# JTAG register map
Vendor: litex
Registers are 32-bit, read-write, reset 0x0 unless marked. A register's access mark holds for its fields unless they carry their own. Offsets are from the block's base; [hi:lo] are bit positions; {n}, {i} and the like mark numbered series.

## BTEVENTS
Base 0xF000D000
0x00 EV_STATUS
  [1:0] status
0x04 EV_PENDING
  [1:0] pending
0x08 EV_ENABLE
  [1:0] enable

## MESSIBLE
Base 0xF000E000
0x00 IN — Write half of the FIFO to send data out the Messible. Writing to this register advances the write pointer automatically.
  [7:0] in
0x04 OUT ro — Read half of the FIFO to receive data on the Messible. Reading from this register advances the read pointer automatically.
  [7:0] out
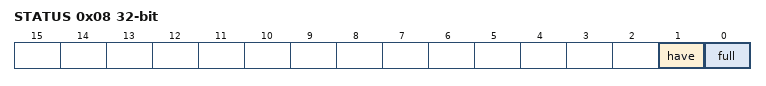
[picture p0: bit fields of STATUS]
0x08 STATUS ro
  [1] have — `1` if data can be read from the OUT FIFO.
  [0] full — `0` if more data can fit into the IN FIFO.

## TICKTIMER
Base 0xF000F000
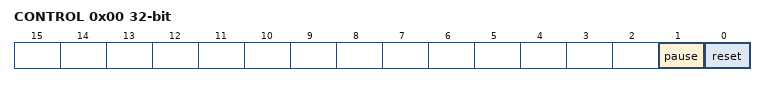
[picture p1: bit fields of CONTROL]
0x00 CONTROL
  [1] pause — Write a `1` to this field to pause counting, 0 for free-run
  [0] reset — Write a `1` to this bit to reset the count to 0
0x04 TIME1 ro — Bits 32-63 of `TICKTIMER_TIME`. Elapsed time in systicks
  [31:0] time
0x08 TIME0 ro — Bits 0-31 of `TICKTIMER_TIME`.
  [31:0] time

## POWER
Base 0xF0010000
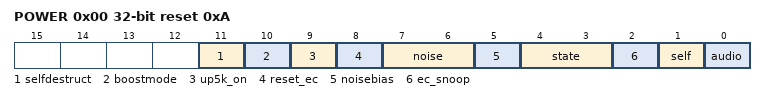
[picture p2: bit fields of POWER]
0x00 POWER reset 0xA
  [11] selfdestruct — Set this bit to clear BBRAM AES key (if used) and cut power in an annoying-to- reset fashion
  [10] boostmode — Writing a `1` causes the USB port to source 5V. To be active only when playing the host role.
  [9] up5k_on — Writing a `1` pulses the UP5K domain to turn on
  [8] reset_ec — Writing a `1` forces EC into reset. Requires write of `0` to release reset.
  [7:6] noise — Controls which of two noise channels are active; all combos valid. noisebias must be on first.
  [5] noisebias — Writing `1` enables the primary bias supply for the noise generator
  [4:3] state — Current SoC power state. 0x=off or not ready, 10=on and safe to shutdown, 11=on and not safe to shut down, resets to 01 to allow extSRAM access immediately during init
  [2] ec_snoop — Writing `1` allows the insecure EC to snoop a couple keyboard pads for wakeup key sequence recognition
  [1] self — Writing `1` forces self power-on (overrides the EC's ability to power me down)
  [0] audio — Write `1` to power on the audio subsystem
0x04 VIBE — Vibration motor configuration register
  [0] vibe — Turn on vibration motor
0x08 EV_STATUS
  [0] status
0x0C EV_PENDING
  [0] pending
0x10 EV_ENABLE
  [0] enable

## SPINOR
Base 0xF0011000
0x00 CONFIG reset 0xA
  [4:0] dummy — Number of dummy cycles
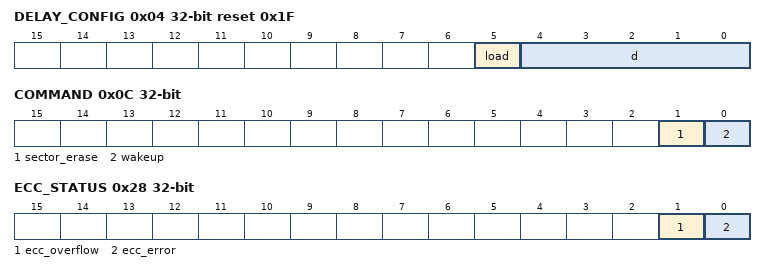
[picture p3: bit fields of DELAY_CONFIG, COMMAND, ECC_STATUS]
0x04 DELAY_CONFIG reset 0x1F
  [5] load — Force delay taps to delay_d
  [4:0] d — Delay amount; each increment is 78ps
0x08 DELAY_STATUS ro
  [4:0] q — Readback of current delay amount, useful if inc/ce is used to set
0x0C COMMAND — Write individual bits to issue special commands to SPI; setting multiple bits at once leads to undefined behavior.
  [1] sector_erase — Erase a sector
  [0] wakeup — Sequence through init & wakeup routine
0x10 SECTOR — Sector to erase
0x14 STATUS ro — Interface status
  [0] wip — Operation in progress (write or erease)
0x18 EV_STATUS
  [0] status
0x1C EV_PENDING
  [0] pending
0x20 EV_ENABLE
  [0] enable
0x24 ECC_ADDRESS ro
  [31:0] ecc_address — Address of the most recent ECC event
0x28 ECC_STATUS ro
  [1] ecc_overflow — More than one ECS_N event has happened since th last time ecc_address was checked
  [0] ecc_error — Live status of the ECS_N bit (ECC error on current packet when low)

## KEYBOARD
Base 0xF0012000
{0x0+4i} ROW{i}DAT ro (i=0..8) — Column data for the given row
  [9:0] row{i}dat
0x24 EV_STATUS
  [0] status
0x28 EV_PENDING
  [0] pending
0x2C EV_ENABLE
  [0] enable
0x30 ROWCHANGE ro — The rows that changed at the point of interrupt generation. Does not update again until the interrupt is serviced.
  [8:0] rowchange

## GPIO
Base 0xF0013000
0x00 OUTPUT — Values to appear on GPIO when respective `drive` bit is asserted
  [5:0] output
0x04 INPUT ro — Value measured on the respective GPIO pin
  [5:0] input
0x08 DRIVE — When a bit is set to `1`, the respective pad drives its value out
  [5:0] drive
0x0C INTENA ro — Enable interrupts when a respective bit is set
  [5:0] intena
0x10 INTPOL ro — When a bit is `1`, falling-edges cause interrupts. Otherwise, rising edges cause interrupts.
  [5:0] intpol
0x14 EV_STATUS
  [5:0] status
0x18 EV_PENDING
  [5:0] pending
0x1C EV_ENABLE
  [5:0] enable
